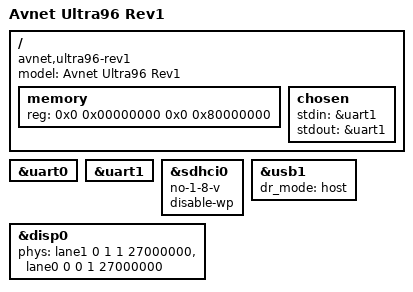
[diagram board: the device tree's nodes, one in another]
/*-
 * Copyright (c) 2018 The FreeBSD Foundation
 * All rights reserved.
 *
 * Redistribution and use in source and binary forms, with or without
 * modification, are permitted provided that the following conditions
 * are met:
 * 1. Redistributions of source code must retain the above copyright
 *    notice, this list of conditions and the following disclaimer.
 * 2. Redistributions in binary form must reproduce the above copyright
 *    notice, this list of conditions and the following disclaimer in the
 *    documentation and/or other materials provided with the distribution.
 *
 * THIS SOFTWARE IS PROVIDED BY THE AUTHOR AND CONTRIBUTORS ``AS IS'' AND
 * ANY EXPRESS OR IMPLIED WARRANTIES, INCLUDING, BUT NOT LIMITED TO, THE
 * IMPLIED WARRANTIES OF MERCHANTABILITY AND FITNESS FOR A PARTICULAR PURPOSE
 * ARE DISCLAIMED. IN NO EVENT SHALL THE AUTHOR OR CONTRIBUTORS BE LIABLE
 * FOR ANY DIRECT, INDIRECT, INCIDENTAL, SPECIAL, EXEMPLARY, OR CONSEQUENTIAL
 * DAMAGES (INCLUDING, BUT NOT LIMITED TO, PROCUREMENT OF SUBSTITUTE GOODS
 * OR SERVICES; LOSS OF USE, DATA, OR PROFITS; OR BUSINESS INTERRUPTION)
 * HOWEVER CAUSED AND ON ANY THEORY OF LIABILITY, WHETHER IN CONTRACT, STRICT
 * LIABILITY, OR TORT (INCLUDING NEGLIGENCE OR OTHERWISE) ARISING IN ANY WAY
 * OUT OF THE USE OF THIS SOFTWARE, EVEN IF ADVISED OF THE POSSIBILITY OF
 * SUCH DAMAGE.
 *
 * $FreeBSD$
 */

/* DTS file for Xilinx Zynq-UltraScale MPSoC based Avnet Ultra96 board. */

/dts-v1/;
/include/ "zynqmp.dtsi"

/ {
	model = "Avnet Ultra96 Rev1";
	compatible = "avnet,ultra96-rev1", "avenet,ultra96",
		     "xlnx,zynqmp-zcu100-revC", "xlnx,zynqmp-zcu100",
		     "xlnx,zynqmp";

	memory {
		device_type = "memory";
		reg =   <0x0 0x00000000 0x0 0x80000000>;
	};

	chosen {
		stdin = &uart1;
		stdout = &uart1;
	};
};

&uart0 {
	status = "okay";
};

&uart1 {
	status = "okay";
};

&sdhci0 {
	status = "okay";
	no-1-8-v;
	disable-wp;
};

&disp0 {
	status = "okay";
	phy-names = "dp-phy0", "dp-phy1";
	phys = <&lane1 0 1 1 27000000>,
	       <&lane0 0 0 1 27000000>;
};

&usb1 {
       status = "okay";
       dr_mode = "host";
};
